AUTOSAR XML (schema 00045)
package /Sdc
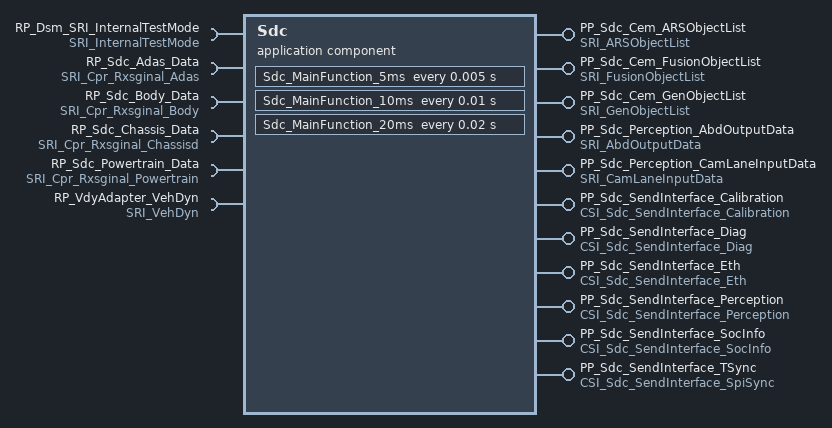
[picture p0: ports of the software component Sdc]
  application sw component type Sdc  # SPI Message Center
    11 x provide port:
      PP_Sdc_Cem_ARSObjectList: provided-interface=SRI_ARSObjectList
      PP_Sdc_Cem_FusionObjectList: provided-interface=SRI_FusionObjectList
      PP_Sdc_Cem_GenObjectList: provided-interface=SRI_GenObjectList
      PP_Sdc_Perception_AbdOutputData: provided-interface=SRI_AbdOutputData
      PP_Sdc_Perception_CamLaneInputData: provided-interface=SRI_CamLaneInputData
      PP_Sdc_SendInterface_Calibration: provided-interface=CSI_Sdc_SendInterface_Calibration
      PP_Sdc_SendInterface_Diag: provided-interface=CSI_Sdc_SendInterface_Diag
      PP_Sdc_SendInterface_Eth: provided-interface=CSI_Sdc_SendInterface_Eth
      PP_Sdc_SendInterface_Perception: provided-interface=CSI_Sdc_SendInterface_Perception
      PP_Sdc_SendInterface_SocInfo: provided-interface=CSI_Sdc_SendInterface_SocInfo
      PP_Sdc_SendInterface_TSync: provided-interface=CSI_Sdc_SendInterface_SpiSync
    6 x require port:
      RP_Dsm_SRI_InternalTestMode: required-interface=SRI_InternalTestMode
      RP_Sdc_Adas_Data: required-interface=SRI_Cpr_Rxsginal_Adas
      RP_Sdc_Body_Data: required-interface=SRI_Cpr_Rxsginal_Body
      RP_Sdc_Chassis_Data: required-interface=SRI_Cpr_Rxsginal_Chassisd
      RP_Sdc_Powertrain_Data: required-interface=SRI_Cpr_Rxsginal_Powertrain
      RP_VdyAdapter_VehDyn: required-interface=SRI_VehDyn
    behavior Sdc_IB: handle-termination-and-restart=NO-SUPPORT
      30 x operation invoked event:
        CalibrationFlag_Read_Event: start-on-event=Sdc_SendInterface_CalibrationFlag_Read, operation=PP_Sdc_SendInterface_Calibration.CalibrationFlag_Read
        CameraCaliresultDetails_Read_Event: start-on-event=Sdc_SendInterface_CameraCaliresultDetails_Read, operation=PP_Sdc_SendInterface_Calibration.CameraCaliresultDetails_Read
        CameraValue_Read_Event: start-on-event=Sdc_SendInterface_CameraValue_Read, operation=PP_Sdc_SendInterface_Calibration.CameraValue_Read
        EOLCalResult_Read_Event: start-on-event=Sdc_SendInterface_EOLCalResult_Read, operation=PP_Sdc_SendInterface_Calibration.EOLCalResult_Read
        EthCableDiagnosticInfo_Read_Event: start-on-event=Sdc_SendInterface_EthCableDiagnosticInfo_Read, operation=PP_Sdc_SendInterface_Eth.EthCableDiagnosticInfo_Read
        EthCableDiagnostic_StartRoutine_Event: start-on-event=Sdc_SendInterface_EthCableDiagnostic_StartRoutine, operation=PP_Sdc_SendInterface_Eth.EthCableDiagnostic_StartRoutine
        EthCableFault_Read_Event: start-on-event=Sdc_SendInterface_EthCableFault_Read, operation=PP_Sdc_SendInterface_Eth.EthCableFault_Read
        EthCableLengthDiagnosticInfo_Read_Event: start-on-event=Sdc_SendInterface_EthCableLengthDiagnosticInfo_Read, operation=PP_Sdc_SendInterface_Eth.EthCableLengthDiagnosticInfo_Read
        EthCableLengthDiagnostic_StartRoutine_Event: start-on-event=Sdc_SendInterface_EthCableLengthDiagnostic_StartRoutine, operation=PP_Sdc_SendInterface_Eth.EthCableLengthDiagnostic_StartRoutine
        EthCrcError_Read_Event: start-on-event=Sdc_SendInterface_EthCrcError_Read, operation=PP_Sdc_SendInterface_Eth.EthCrcError_Read
        EthEnableTestModeInfo_Read_Event: start-on-event=Sdc_SendInterface_EthEnableTestModeInfo_Read, operation=PP_Sdc_SendInterface_Eth.EthEnableTestModeInfo_Read
        EthEnableTestMode_StartRoutine_Event: start-on-event=Sdc_SendInterface_EthEnableTestMode_StartRoutine, operation=PP_Sdc_SendInterface_Eth.EthEnableTestMode_StartRoutine
        EthEnableTestMode_StopRoutine_Event: start-on-event=Sdc_SendInterface_EthEnableTestMode_StopRoutine, operation=PP_Sdc_SendInterface_Eth.EthEnableTestMode_StopRoutine
        EthIcmpError_Read_Event: start-on-event=Sdc_SendInterface_EthIcmpError_Read, operation=PP_Sdc_SendInterface_Eth.EthIcmpError_Read
        EthPhyLoopBackTestInfo_Read_Event: start-on-event=Sdc_SendInterface_EthPhyLoopBackTestInfo_Read, operation=PP_Sdc_SendInterface_Eth.EthPhyLoopBackTestInfo_Read
        EthPhyLoopBackTest_StartRoutine_Event: start-on-event=Sdc_SendInterface_EthPhyLoopBackTest_StartRoutine, operation=PP_Sdc_SendInterface_Eth.EthPhyLoopBackTest_StartRoutine
        EthPhyLoopBackTest_StopRoutine_Event: start-on-event=Sdc_SendInterface_EthPhyLoopBackTest_StopRoutine, operation=PP_Sdc_SendInterface_Eth.EthPhyLoopBackTest_StopRoutine
        EthReadPhyRegisterInfo_Read_Event: start-on-event=Sdc_SendInterface_EthReadPhyRegisterInfo_Read, operation=PP_Sdc_SendInterface_Eth.EthReadPhyRegisterInfo_Read
        EthReadPhyRegister_StartRoutine_Event: start-on-event=Sdc_SendInterface_EthReadPhyRegister_StartRoutine, operation=PP_Sdc_SendInterface_Eth.EthReadPhyRegister_StartRoutine
        EthResetMACAddressInfo_Read_Event: start-on-event=Sdc_SendInterface_EthResetMACAddressInfo_Read, operation=PP_Sdc_SendInterface_Eth.EthResetMACAddressInfo_Read
        EthResetMACAddress_StartRoutine_Event: start-on-event=Sdc_SendInterface_EthResetMACAddress_StartRoutine, operation=PP_Sdc_SendInterface_Eth.EthResetMACAddress_StartRoutine
        EthResetMACLayerStatisticInfo_Read_Event: start-on-event=Sdc_SendInterface_EthResetMACLayerStatisticInfo_Read, operation=PP_Sdc_SendInterface_Eth.EthResetMACLayerStatisticInfo_Read
        EthResetMACLayerStatistic_StartRoutine_Event: start-on-event=Sdc_SendInterface_EthResetMACLayerStatistic_StartRoutine, operation=PP_Sdc_SendInterface_Eth.EthResetMACLayerStatistic_StartRoutine
        EthResetPortConfigurationInfo_Read_Event: start-on-event=Sdc_SendInterface_EthResetPortConfigurationInfo_Read, operation=PP_Sdc_SendInterface_Eth.EthResetPortConfigurationInfo_Read
        EthResetPortConfiguration_StartRoutine_Event: start-on-event=Sdc_SendInterface_EthResetPortConfiguration_StartRoutine, operation=PP_Sdc_SendInterface_Eth.EthResetPortConfiguration_StartRoutine
        EthSQI_Read_Event: start-on-event=Sdc_SendInterface_EthSQI_Read, operation=PP_Sdc_SendInterface_Eth.EthSQI_Read
        EthSetPortConfigurationInfo_Read_Event: start-on-event=Sdc_SendInterface_EthSetPortConfigurationInfo_Read, operation=PP_Sdc_SendInterface_Eth.EthSetPortConfigurationInfo_Read
        EthSetPortConfiguration_StartRoutine_Event: start-on-event=Sdc_SendInterface_EthSetPortConfiguration_StartRoutine, operation=PP_Sdc_SendInterface_Eth.EthSetPortConfiguration_StartRoutine
        HostLane_Left_flag_Read_Event: start-on-event=Sdc_SendInterface_HostLane_Left_flag_Read, operation=PP_Sdc_SendInterface_Perception.HostLane_Left_flag_Read
        HostLane_Right_flag_Read_Event: start-on-event=Sdc_SendInterface_HostLane_Right_flag_Read, operation=PP_Sdc_SendInterface_Perception.HostLane_Right_flag_Read
      init event InitEvent_Sdc_InitFunction: start-on-event=Sdc_InitFunction
      16 x operation invoked event:
        J3_PerceptionData_Read_Event: start-on-event=Sdc_SendInterface_J3_PerceptionData_Read, operation=PP_Sdc_SendInterface_Perception.J3_PerceptionData_Read
        Len_to_Left_Lane_Read_Event: start-on-event=Sdc_SendInterface_Len_to_Left_Lane_Read, operation=PP_Sdc_SendInterface_Perception.Len_to_Left_Lane_Read
        Len_to_Right_Lane_Read_Event: start-on-event=Sdc_SendInterface_Len_to_Right_Lane_Read, operation=PP_Sdc_SendInterface_Perception.Len_to_Right_Lane_Read
        PWMState_Read_Event: start-on-event=Sdc_SendInterface_PWMState_Read, operation=PP_Sdc_SendInterface_SocInfo.PWMState_Read
        RequestBootSensor_Event: start-on-event=Sdc_SendInterface_RequestBootSensor, operation=PP_Sdc_SendInterface_SocInfo.RequestBootSensor
        RequestCalibrationValue_Event: start-on-event=Sdc_SendInterface_RequestCalibrationValue, operation=PP_Sdc_SendInterface_Calibration.RequestCalibrationValue
        RequestEOLCalibration_Event: start-on-event=Sdc_SendInterface_RequestEOLCalibration, operation=PP_Sdc_SendInterface_Calibration.RequestEOLCalibration
        RequestOMSN_Event: start-on-event=Sdc_SendInterface_RequestOMSN, operation=PP_Sdc_SendInterface_SocInfo.RequestOMSN
        RequestSDACalibration_Event: start-on-event=Sdc_SendInterface_RequestSDACalibration, operation=PP_Sdc_SendInterface_Calibration.RequestSDACalibration
        SocBootSensor_Read_Event: start-on-event=Sdc_SendInterface_SocBootSensor_Read, operation=PP_Sdc_SendInterface_SocInfo.SocBootSensor_Read
        SocCpuInfo_Read_Event: start-on-event=Sdc_SendInterface_SocCpuInfo_Read, operation=PP_Sdc_SendInterface_SocInfo.SocCpuInfo_Read
        SocDiagInfo_Read_Event: start-on-event=Sdc_SendInterface_SocDiagInfo_Read, operation=PP_Sdc_SendInterface_Diag.SocDiagInfo_Read
        SocOMSN_Read_Event: start-on-event=Sdc_SendInterface_SocOMSN_Read, operation=PP_Sdc_SendInterface_SocInfo.SocOMSN_Read
        SocShutdownReuqest_Event: start-on-event=Sdc_SendInterface_SocShutdownReuqest, operation=PP_Sdc_SendInterface_SocInfo.SocShutdownReuqest
        SocSysState_Read_Event: start-on-event=Sdc_SendInterface_SocSysState_Read, operation=PP_Sdc_SendInterface_Diag.SocSysState_Read
        Time_Event: start-on-event=Sdc_SendInterface_TimeSyncMsg, operation=PP_Sdc_SendInterface_TSync.TimeSyncMsg
      timing event TimingEvent_Sdc_MainFunction_5ms: start-on-event=Sdc_MainFunction_5ms, period=0.005
      timing event TimingEvt_Sdc_MainFunction_10ms: start-on-event=Sdc_MainFunction_10ms, period=0.01
      timing event TimingEvt_Sdc_MainFunction_20ms: start-on-event=Sdc_MainFunction_20ms, period=0.02
      operation invoked event UTC_Event: start-on-event=Sdc_SendInterface_TimeSyncUtc, operation=PP_Sdc_SendInterface_TSync.TimeSyncUtc
      operation invoked event UdsRequest_Event: start-on-event=Sdc_SendInterface_UdsRequest, operation=PP_Sdc_SendInterface_Diag.UdsRequest
      52 x runnable:
        Sdc_InitFunction
        Sdc_MainFunction_10ms
          data-receive-point-by-arguments:
            21 x access:
              drparg_BCM_TurnLightSwitchSt: accessed-variable=RP_Sdc_Body_Data.BCM_TurnLightSwitchSts_Status
              drparg_BCM_TurnLightSwitchSts: accessed-variable=RP_Sdc_Body_Data.BCM_TurnLightSwitchSts
              drparg_BcmFrntWiperSts: accessed-variable=RP_Sdc_Body_Data.BcmFrntWiperSts
              drparg_BcmFrntWiperSts_Status: accessed-variable=RP_Sdc_Body_Data.BcmFrntWiperSts_Status
              drparg_BcmHiBeamSts: accessed-variable=RP_Sdc_Body_Data.BcmHiBeamSts
              drparg_BcmHiBeamSts_Status: accessed-variable=RP_Sdc_Body_Data.BcmHiBeamSts_Status
              drparg_ESP_LongAccelValid: accessed-variable=RP_Sdc_Chassis_Data.ESP_LongAccelValid
              drparg_ESP_YawRateValid: accessed-variable=RP_Sdc_Chassis_Data.ESP_YawRateValid
              drparg_EpsSasSteerAg: accessed-variable=RP_Sdc_Chassis_Data.EpsSasSteerAg
              drparg_EpsSasSteerAgVld: accessed-variable=RP_Sdc_Chassis_Data.EpsSasSteerAgVld
              drparg_EpsSasSteerAg_Status: accessed-variable=RP_Sdc_Chassis_Data.EpsSasSteerAg_Status
              drparg_EpsSteerAgRate: accessed-variable=RP_Sdc_Chassis_Data.EpsSteerAgRate
              drparg_EspLongAccel: accessed-variable=RP_Sdc_Chassis_Data.EspLongAccel
              drparg_EspLongAccel_Status: accessed-variable=RP_Sdc_Chassis_Data.EspLongAccel_Status
              drparg_EspVehSpd: accessed-variable=RP_Sdc_Chassis_Data.EspVehSpd
              drparg_EspVehSpdVld: accessed-variable=RP_Sdc_Chassis_Data.EspVehSpdVld
              drparg_EspVehSpd_Status: accessed-variable=RP_Sdc_Chassis_Data.EspVehSpd_Status
              drparg_EspYawRate: accessed-variable=RP_Sdc_Chassis_Data.EspYawRate
              drparg_EspYawRate_Status: accessed-variable=RP_Sdc_Chassis_Data.EspYawRate_Status
              drparg_VcuGearPosn: accessed-variable=RP_Sdc_Chassis_Data.VcuGearPosn
              drparg_VcuGearPosn_Status: accessed-variable=RP_Sdc_Chassis_Data.VcuGearPosn_Status
        Sdc_MainFunction_20ms
        Sdc_MainFunction_5ms
          data-receive-point-by-arguments:
            access drparg_VehDyn: accessed-variable=RP_VdyAdapter_VehDyn.VehDyn
          data-send-points:
            5 x access:
              dsp_ARSObjectList: accessed-variable=PP_Sdc_Cem_ARSObjectList.ARSObjectList
              dsp_AbdOutputData_t: accessed-variable=PP_Sdc_Perception_AbdOutputData.AbdOutputData_t
              dsp_CamLaneInputData: accessed-variable=PP_Sdc_Perception_CamLaneInputData.CamLaneInputData
              dsp_FusionObjectList: accessed-variable=PP_Sdc_Cem_FusionObjectList.FusionObjectList
              dsp_GenObjectList: accessed-variable=PP_Sdc_Cem_GenObjectList.GenObjectList
        Sdc_SendInterface_CalibrationFlag_Read
        Sdc_SendInterface_CameraCaliresultDetails_Read
        Sdc_SendInterface_CameraValue_Read
        Sdc_SendInterface_EOLCalResult_Read
        Sdc_SendInterface_EthCableDiagnosticInfo_Read
        Sdc_SendInterface_EthCableDiagnostic_StartRoutine
        Sdc_SendInterface_EthCableFault_Read
        Sdc_SendInterface_EthCableLengthDiagnosticInfo_Read
        Sdc_SendInterface_EthCableLengthDiagnostic_StartRoutine
        Sdc_SendInterface_EthCrcError_Read
        Sdc_SendInterface_EthEnableTestModeInfo_Read
        Sdc_SendInterface_EthEnableTestMode_StartRoutine
        Sdc_SendInterface_EthEnableTestMode_StopRoutine
        Sdc_SendInterface_EthIcmpError_Read
        Sdc_SendInterface_EthPhyLoopBackTestInfo_Read
        Sdc_SendInterface_EthPhyLoopBackTest_StartRoutine
        Sdc_SendInterface_EthPhyLoopBackTest_StopRoutine
        Sdc_SendInterface_EthReadPhyRegisterInfo_Read
        Sdc_SendInterface_EthReadPhyRegister_StartRoutine
        Sdc_SendInterface_EthResetMACAddressInfo_Read
        Sdc_SendInterface_EthResetMACAddress_StartRoutine
        Sdc_SendInterface_EthResetMACLayerStatisticInfo_Read
        Sdc_SendInterface_EthResetMACLayerStatistic_StartRoutine
        Sdc_SendInterface_EthResetPortConfigurationInfo_Read
        Sdc_SendInterface_EthResetPortConfiguration_StartRoutine
        Sdc_SendInterface_EthSQI_Read
        Sdc_SendInterface_EthSetPortConfigurationInfo_Read
        Sdc_SendInterface_EthSetPortConfiguration_StartRoutine
        Sdc_SendInterface_HostLane_Left_flag_Read
        Sdc_SendInterface_HostLane_Right_flag_Read
        Sdc_SendInterface_J3_PerceptionData_Read
        Sdc_SendInterface_Len_to_Left_Lane_Read
        Sdc_SendInterface_Len_to_Right_Lane_Read
        Sdc_SendInterface_PWMState_Read
        Sdc_SendInterface_RequestBootSensor
        Sdc_SendInterface_RequestCalibrationValue
        Sdc_SendInterface_RequestEOLCalibration
        Sdc_SendInterface_RequestOMSN
        Sdc_SendInterface_RequestSDACalibration
        Sdc_SendInterface_SocBootSensor_Read
        Sdc_SendInterface_SocCpuInfo_Read
        Sdc_SendInterface_SocDiagInfo_Read
          data-receive-point-by-arguments:
            access drparg_DE_InternalTestMode: accessed-variable=RP_Dsm_SRI_InternalTestMode.DE_InternalTestMode
        Sdc_SendInterface_SocOMSN_Read
        Sdc_SendInterface_SocShutdownReuqest
        Sdc_SendInterface_SocSysState_Read
        Sdc_SendInterface_TimeSyncMsg
        Sdc_SendInterface_TimeSyncUtc
        Sdc_SendInterface_UdsRequest
  swc implementation SdcImpl: programming-language=C, sw-version=0.0.1, vendor-id=0, behavior=Sdc_IB
    code-descriptors:
      code CodeGen: artifact-descriptors=[{short-label=SWSRC, category=SWSRC}, {short-label=SWHDR, category=SWHDR}]
    resource consumption Resource
      memory section CODE: sw-addrmethod=CODE
      memory section VAR_UNSPECIFIED: sw-addrmethod=VAR
